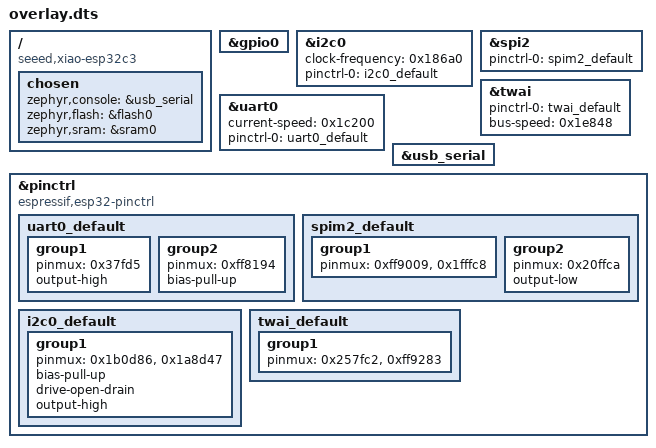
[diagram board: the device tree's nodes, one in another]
/ {
	compatible = "seeed,xiao-esp32c3";
	chosen {
		zephyr,console = &usb_serial;
		zephyr,flash = &flash0;
		zephyr,sram = &sram0;
	};
};
&gpio0{
	status = "okay";
};
&i2c0{
	status = "okay";
	clock-frequency = < 0x186a0 >;
	pinctrl-0 = < &i2c0_default >;
	pinctrl-names = "default";
};
&spi2{
	status = "okay";
	#address-cells = < 0x1 >;
	#size-cells = < 0x0 >;
	pinctrl-0 = < &spim2_default >;
	pinctrl-names = "default";
};
&twai{
	status = "okay";
	pinctrl-0 = < &twai_default >;
	pinctrl-names = "default";
	bus-speed = < 0x1e848 >;
};
&uart0{
	status = "okay";
	current-speed = < 0x1c200 >;
	pinctrl-0 = < &uart0_default >;
	pinctrl-names = "default";
};
&usb_serial{
	status = "okay";
};
&pinctrl{
	compatible = "espressif,esp32-pinctrl";
	status = "okay";
	uart0_default: uart0_default {
		group1 {
			pinmux = < 0x37fd5 >;
			output-high;
		};
		group2 {
			pinmux = < 0xff8194 >;
			bias-pull-up;
		};
	};
	spim2_default: spim2_default {
		group1 {
			pinmux = < 0xff9009 >, < 0x1fffc8 >;
		};
		group2 {
			pinmux = < 0x20ffca >;
			output-low;
		};
	};
	i2c0_default: i2c0_default {
		group1 {
			pinmux = < 0x1b0d86 >, < 0x1a8d47 >;
			bias-pull-up;
			drive-open-drain;
			output-high;
		};
	};
	twai_default: twai_default {
		group1 {
			pinmux = < 0x257fc2 >, < 0xff9283 >;
		};
	};
};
